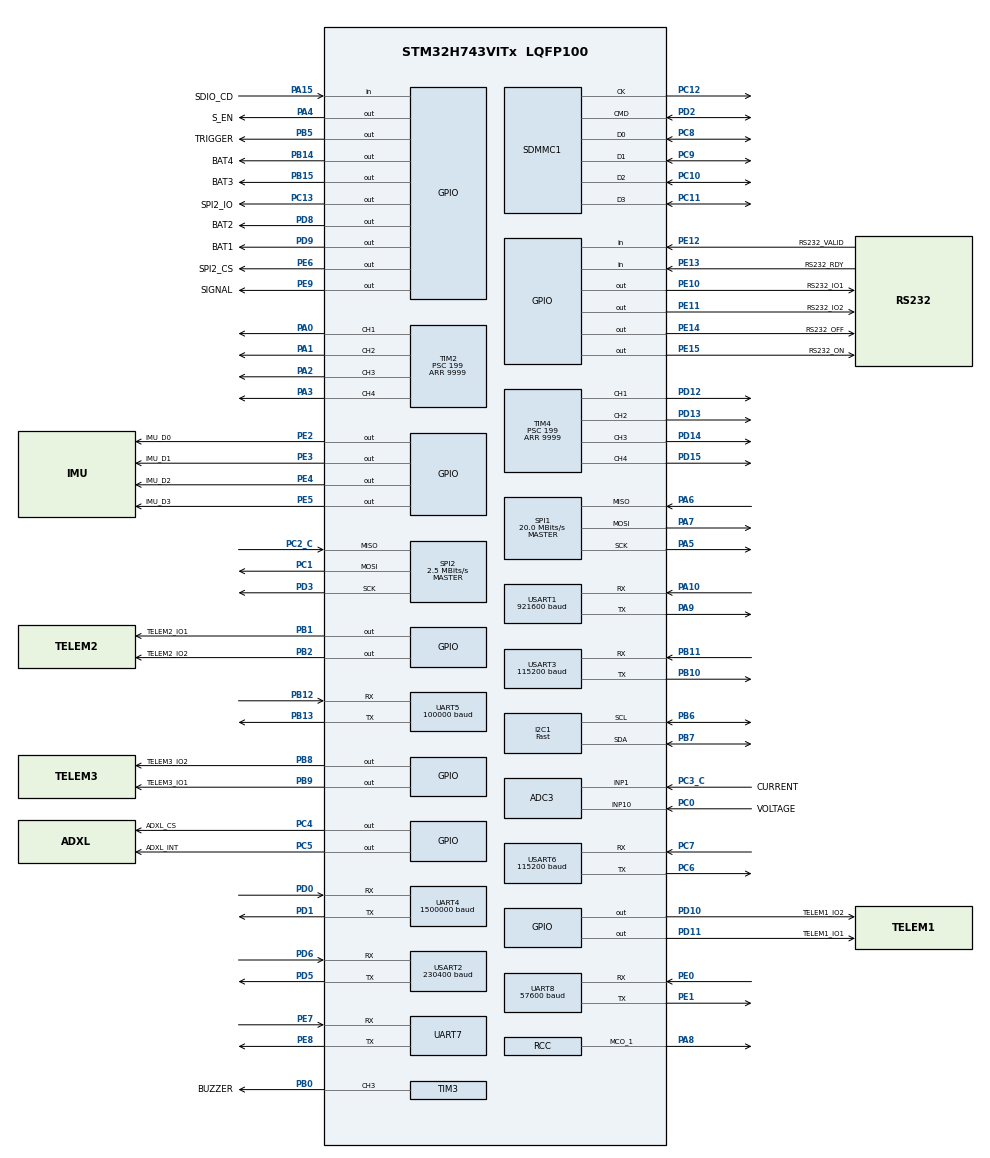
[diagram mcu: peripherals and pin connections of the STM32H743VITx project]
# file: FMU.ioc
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ADC3.Channel-7\#ChannelRegularConversion=ADC_CHANNEL_1
ADC3.Channel-8\#ChannelRegularConversion=ADC_CHANNEL_10
ADC3.ClockPrescalerADC3=ADC_CLOCK_ASYNC_DIV4
ADC3.DiscontinuousConvMode=ENABLE
ADC3.NbrOfConversion=2
ADC3.NbrOfConversionFlag=1
ADC3.OffsetNumber-7\#ChannelRegularConversion=ADC_OFFSET_NONE
ADC3.OffsetNumber-8\#ChannelRegularConversion=ADC_OFFSET_NONE
ADC3.OffsetSignedSaturation-7\#ChannelRegularConversion=DISABLE
ADC3.OffsetSignedSaturation-8\#ChannelRegularConversion=DISABLE
ADC3.Rank-7\#ChannelRegularConversion=1
ADC3.Rank-8\#ChannelRegularConversion=2
ADC3.SamplingTime-7\#ChannelRegularConversion=ADC_SAMPLETIME_387CYCLES_5
ADC3.SamplingTime-8\#ChannelRegularConversion=ADC_SAMPLETIME_387CYCLES_5
Dma.Request0=UART5_RX
Dma.Request1=USART3_RX
Dma.Request2=UART4_RX
Dma.Request3=USART2_RX
Dma.Request4=UART8_TX
Dma.Request5=USART6_RX
Dma.Request6=USART1_TX
Dma.Request7=UART8_RX
Dma.UART4_RX.2.Direction=DMA_PERIPH_TO_MEMORY
Dma.UART4_RX.2.EventEnable=DISABLE
Dma.UART4_RX.2.FIFOMode=DMA_FIFOMODE_DISABLE
Dma.UART4_RX.2.Instance=DMA1_Stream2
Dma.UART4_RX.2.MemDataAlignment=DMA_MDATAALIGN_BYTE
Dma.UART4_RX.2.MemInc=DMA_MINC_ENABLE
Dma.UART4_RX.2.Mode=DMA_NORMAL
Dma.UART4_RX.2.PeriphDataAlignment=DMA_PDATAALIGN_BYTE
Dma.UART4_RX.2.PeriphInc=DMA_PINC_DISABLE
Dma.UART4_RX.2.Polarity=HAL_DMAMUX_REQ_GEN_RISING
Dma.UART4_RX.2.Priority=DMA_PRIORITY_LOW
Dma.UART4_RX.2.RequestNumber=1
Dma.UART4_RX.2.SignalID=NONE
Dma.UART4_RX.2.SyncEnable=DISABLE
Dma.UART4_RX.2.SyncPolarity=HAL_DMAMUX_SYNC_NO_EVENT
Dma.UART4_RX.2.SyncRequestNumber=1
Dma.UART4_RX.2.SyncSignalID=NONE
Dma.UART5_RX.0.Direction=DMA_PERIPH_TO_MEMORY
Dma.UART5_RX.0.EventEnable=DISABLE
Dma.UART5_RX.0.FIFOMode=DMA_FIFOMODE_DISABLE
Dma.UART5_RX.0.Instance=DMA1_Stream0
Dma.UART5_RX.0.MemDataAlignment=DMA_MDATAALIGN_BYTE
Dma.UART5_RX.0.MemInc=DMA_MINC_ENABLE
Dma.UART5_RX.0.Mode=DMA_NORMAL
Dma.UART5_RX.0.PeriphDataAlignment=DMA_PDATAALIGN_BYTE
Dma.UART5_RX.0.PeriphInc=DMA_PINC_DISABLE
Dma.UART5_RX.0.Polarity=HAL_DMAMUX_REQ_GEN_RISING
Dma.UART5_RX.0.Priority=DMA_PRIORITY_VERY_HIGH
Dma.UART5_RX.0.RequestNumber=1
Dma.UART5_RX.0.SignalID=NONE
Dma.UART5_RX.0.SyncEnable=DISABLE
Dma.UART5_RX.0.SyncPolarity=HAL_DMAMUX_SYNC_NO_EVENT
Dma.UART5_RX.0.SyncRequestNumber=1
Dma.UART5_RX.0.SyncSignalID=NONE
Dma.UART8_RX.7.Direction=DMA_PERIPH_TO_MEMORY
Dma.UART8_RX.7.EventEnable=DISABLE
Dma.UART8_RX.7.FIFOMode=DMA_FIFOMODE_DISABLE
Dma.UART8_RX.7.Instance=DMA2_Stream0
Dma.UART8_RX.7.MemDataAlignment=DMA_MDATAALIGN_BYTE
Dma.UART8_RX.7.MemInc=DMA_MINC_ENABLE
Dma.UART8_RX.7.Mode=DMA_NORMAL
Dma.UART8_RX.7.PeriphDataAlignment=DMA_PDATAALIGN_BYTE
Dma.UART8_RX.7.PeriphInc=DMA_PINC_DISABLE
Dma.UART8_RX.7.Polarity=HAL_DMAMUX_REQ_GEN_RISING
Dma.UART8_RX.7.Priority=DMA_PRIORITY_HIGH
Dma.UART8_RX.7.RequestNumber=1
Dma.UART8_RX.7.SignalID=NONE
Dma.UART8_RX.7.SyncEnable=DISABLE
Dma.UART8_RX.7.SyncPolarity=HAL_DMAMUX_SYNC_NO_EVENT
Dma.UART8_RX.7.SyncRequestNumber=1
Dma.UART8_RX.7.SyncSignalID=NONE
Dma.UART8_TX.4.Direction=DMA_MEMORY_TO_PERIPH
Dma.UART8_TX.4.EventEnable=DISABLE
Dma.UART8_TX.4.FIFOMode=DMA_FIFOMODE_DISABLE
Dma.UART8_TX.4.Instance=DMA1_Stream4
Dma.UART8_TX.4.MemDataAlignment=DMA_MDATAALIGN_BYTE
Dma.UART8_TX.4.MemInc=DMA_MINC_ENABLE
Dma.UART8_TX.4.Mode=DMA_NORMAL
Dma.UART8_TX.4.PeriphDataAlignment=DMA_PDATAALIGN_BYTE
Dma.UART8_TX.4.PeriphInc=DMA_PINC_DISABLE
Dma.UART8_TX.4.Polarity=HAL_DMAMUX_REQ_GEN_RISING
Dma.UART8_TX.4.Priority=DMA_PRIORITY_LOW
Dma.UART8_TX.4.RequestNumber=1
Dma.UART8_TX.4.SignalID=NONE
Dma.UART8_TX.4.SyncEnable=DISABLE
Dma.UART8_TX.4.SyncPolarity=HAL_DMAMUX_SYNC_NO_EVENT
Dma.UART8_TX.4.SyncRequestNumber=1
Dma.UART8_TX.4.SyncSignalID=NONE
Dma.USART1_TX.6.Direction=DMA_MEMORY_TO_PERIPH
Dma.USART1_TX.6.EventEnable=DISABLE
Dma.USART1_TX.6.FIFOMode=DMA_FIFOMODE_DISABLE
Dma.USART1_TX.6.Instance=DMA1_Stream6
Dma.USART1_TX.6.MemDataAlignment=DMA_MDATAALIGN_BYTE
Dma.USART1_TX.6.MemInc=DMA_MINC_ENABLE
Dma.USART1_TX.6.Mode=DMA_NORMAL
Dma.USART1_TX.6.PeriphDataAlignment=DMA_PDATAALIGN_BYTE
Dma.USART1_TX.6.PeriphInc=DMA_PINC_DISABLE
Dma.USART1_TX.6.Polarity=HAL_DMAMUX_REQ_GEN_RISING
Dma.USART1_TX.6.Priority=DMA_PRIORITY_LOW
Dma.USART1_TX.6.RequestNumber=1
Dma.USART1_TX.6.SignalID=NONE
Dma.USART1_TX.6.SyncEnable=DISABLE
Dma.USART1_TX.6.SyncPolarity=HAL_DMAMUX_SYNC_NO_EVENT
Dma.USART1_TX.6.SyncRequestNumber=1
Dma.USART1_TX.6.SyncSignalID=NONE
Dma.USART2_RX.3.Direction=DMA_PERIPH_TO_MEMORY
Dma.USART2_RX.3.EventEnable=DISABLE
Dma.USART2_RX.3.FIFOMode=DMA_FIFOMODE_DISABLE
Dma.USART2_RX.3.Instance=DMA1_Stream3
Dma.USART2_RX.3.MemDataAlignment=DMA_MDATAALIGN_BYTE
Dma.USART2_RX.3.MemInc=DMA_MINC_ENABLE
Dma.USART2_RX.3.Mode=DMA_NORMAL
Dma.USART2_RX.3.PeriphDataAlignment=DMA_PDATAALIGN_BYTE
Dma.USART2_RX.3.PeriphInc=DMA_PINC_DISABLE
Dma.USART2_RX.3.Polarity=HAL_DMAMUX_REQ_GEN_RISING
Dma.USART2_RX.3.Priority=DMA_PRIORITY_VERY_HIGH
Dma.USART2_RX.3.RequestNumber=1
Dma.USART2_RX.3.SignalID=NONE
Dma.USART2_RX.3.SyncEnable=DISABLE
Dma.USART2_RX.3.SyncPolarity=HAL_DMAMUX_SYNC_NO_EVENT
Dma.USART2_RX.3.SyncRequestNumber=1
Dma.USART2_RX.3.SyncSignalID=NONE
Dma.USART3_RX.1.Direction=DMA_PERIPH_TO_MEMORY
Dma.USART3_RX.1.EventEnable=DISABLE
Dma.USART3_RX.1.FIFOMode=DMA_FIFOMODE_DISABLE
Dma.USART3_RX.1.Instance=DMA1_Stream1
Dma.USART3_RX.1.MemDataAlignment=DMA_MDATAALIGN_BYTE
Dma.USART3_RX.1.MemInc=DMA_MINC_ENABLE
Dma.USART3_RX.1.Mode=DMA_NORMAL
Dma.USART3_RX.1.PeriphDataAlignment=DMA_PDATAALIGN_BYTE
Dma.USART3_RX.1.PeriphInc=DMA_PINC_DISABLE
Dma.USART3_RX.1.Polarity=HAL_DMAMUX_REQ_GEN_RISING
Dma.USART3_RX.1.Priority=DMA_PRIORITY_MEDIUM
Dma.USART3_RX.1.RequestNumber=1
Dma.USART3_RX.1.SignalID=NONE
Dma.USART3_RX.1.SyncEnable=DISABLE
Dma.USART3_RX.1.SyncPolarity=HAL_DMAMUX_SYNC_NO_EVENT
Dma.USART3_RX.1.SyncRequestNumber=1
Dma.USART3_RX.1.SyncSignalID=NONE
Dma.USART6_RX.5.Direction=DMA_PERIPH_TO_MEMORY
Dma.USART6_RX.5.EventEnable=DISABLE
Dma.USART6_RX.5.FIFOMode=DMA_FIFOMODE_DISABLE
Dma.USART6_RX.5.Instance=DMA1_Stream5
Dma.USART6_RX.5.MemDataAlignment=DMA_MDATAALIGN_BYTE
Dma.USART6_RX.5.MemInc=DMA_MINC_ENABLE
Dma.USART6_RX.5.Mode=DMA_NORMAL
Dma.USART6_RX.5.PeriphDataAlignment=DMA_PDATAALIGN_BYTE
Dma.USART6_RX.5.PeriphInc=DMA_PINC_DISABLE
Dma.USART6_RX.5.Polarity=HAL_DMAMUX_REQ_GEN_RISING
Dma.USART6_RX.5.Priority=DMA_PRIORITY_MEDIUM
Dma.USART6_RX.5.RequestNumber=1
Dma.USART6_RX.5.SignalID=NONE
Dma.USART6_RX.5.SyncEnable=DISABLE
Dma.USART6_RX.5.SyncPolarity=HAL_DMAMUX_SYNC_NO_EVENT
Dma.USART6_RX.5.SyncRequestNumber=1
Dma.USART6_RX.5.SyncSignalID=NONE
FATFS.BSP.number=1
FATFS._CODE_PAGE=936
FATFS._STRF_ENCODE=0
FATFS._USE_LFN=3
FATFS0.BSP.STBoard=false
FATFS0.BSP.api=Unknown
FATFS0.BSP.instance=PA15 (JTDI)
FATFS0.BSP.ip=GPIO
FATFS0.BSP.mode=Input
FATFS0.BSP.name=Detect_SDIO
FATFS0.BSP.solution=PA15 (JTDI)
FREERTOS.Tasks01=defaultTask,0,256,StartDefaultTask,Default,NULL,Dynamic,NULL,NULL
FREERTOS.configENABLE_BACKWARD_COMPATIBILITY=0
FREERTOS.configENABLE_FPU=1
FREERTOS.configGENERATE_RUN_TIME_STATS=1
FREERTOS.configMAX_PRIORITIES=32
FREERTOS.configMAX_TASK_NAME_LEN=50
FREERTOS.configMINIMAL_STACK_SIZE=64
FREERTOS.configTICK_RATE_HZ=200
FREERTOS.configUSE_COUNTING_SEMAPHORES=1
FREERTOS.configUSE_STATS_FORMATTING_FUNCTIONS=1
FREERTOS.configUSE_TIMERS=0
FREERTOS.configUSE_TRACE_FACILITY=1
I2C1.I2C_Speed_Mode=I2C_Fast
I2C1.Timing=0x009034B6
Mcu.Family=STM32H7
Mcu.Name=STM32H743VITx
Mcu.Package=LQFP100
NVIC.DMA1_Stream0_IRQn=true\:5\:0\:false\:false\:true\:true\:false\:true\:true
NVIC.DMA1_Stream1_IRQn=true\:5\:0\:false\:false\:true\:true\:false\:true\:true
NVIC.DMA1_Stream2_IRQn=true\:5\:0\:false\:false\:true\:true\:false\:true\:true
NVIC.DMA1_Stream3_IRQn=true\:5\:0\:false\:false\:true\:true\:false\:true\:true
NVIC.DMA1_Stream4_IRQn=true\:5\:0\:false\:false\:true\:true\:false\:true\:true
NVIC.DMA1_Stream5_IRQn=true\:5\:0\:false\:false\:true\:true\:false\:true\:true
NVIC.DMA1_Stream6_IRQn=true\:5\:0\:false\:false\:true\:true\:false\:true\:true
NVIC.DMA2_Stream0_IRQn=true\:5\:0\:false\:false\:true\:true\:false\:true\:true
NVIC.PriorityGroup=NVIC_PRIORITYGROUP_4
NVIC.SDMMC1_IRQn=true\:6\:0\:true\:false\:true\:true\:true\:true\:true
NVIC.TIM17_IRQn=true\:15\:0\:false\:false\:true\:false\:false\:true\:true
NVIC.TIM6_DAC_IRQn=true\:5\:0\:false\:false\:true\:true\:true\:true\:true
NVIC.TIM7_IRQn=true\:5\:0\:false\:false\:true\:true\:true\:true\:true
NVIC.TimeBase=TIM17_IRQn
NVIC.TimeBaseIP=TIM17
NVIC.UART5_IRQn=true\:5\:0\:true\:false\:true\:true\:true\:true\:true
NVIC.UART8_IRQn=true\:5\:0\:false\:false\:true\:true\:true\:true\:true
NVIC.USART1_IRQn=true\:5\:0\:false\:false\:true\:true\:true\:true\:true
NVIC.USART2_IRQn=true\:6\:0\:true\:false\:true\:true\:true\:true\:true
NVIC.USART3_IRQn=true\:9\:0\:true\:false\:true\:true\:true\:true\:true
NVIC.USART6_IRQn=true\:5\:0\:false\:false\:true\:true\:true\:true\:true
PA0.Signal=S_TIM2_CH1_ETR
PA1.Signal=S_TIM2_CH2
PA10.Mode=Asynchronous
PA10.Signal=USART1_RX
PA13\ (JTMS/SWDIO).Mode=Serial_Wire
PA13\ (JTMS/SWDIO).Signal=DEBUG_JTMS-SWDIO
PA14\ (JTCK/SWCLK).Mode=Serial_Wire
PA14\ (JTCK/SWCLK).Signal=DEBUG_JTCK-SWCLK
PA15\ (JTDI).GPIO_Label=SDIO_CD
PA15\ (JTDI).Signal=GPIO_Input
PA2.Signal=S_TIM2_CH3
PA3.Signal=S_TIM2_CH4
PA4.GPIO_Label=S_EN
PA4.GPIO_ModeDefaultOutputPP=GPIO_MODE_OUTPUT_OD
PA4.GPIO_PuPd=GPIO_NOPULL
PA4.PinState=GPIO_PIN_SET
PA4.Signal=GPIO_Output
PA5.Mode=Full_Duplex_Master
PA5.Signal=SPI1_SCK
PA6.Mode=Full_Duplex_Master
PA6.Signal=SPI1_MISO
PA7.Mode=Full_Duplex_Master
PA7.Signal=SPI1_MOSI
PA8.Mode=Clock-out-1
PA8.Signal=RCC_MCO_1
PA9.Mode=Asynchronous
PA9.Signal=USART1_TX
PB0.GPIO_Label=BUZZER
PB0.Signal=S_TIM3_CH3
PB1.GPIO_Label=TELEM2_IO1
PB1.GPIO_PuPd=GPIO_PULLDOWN
PB1.GPIO_Speed=GPIO_SPEED_FREQ_LOW
PB1.PinState=GPIO_PIN_RESET
PB1.Signal=GPIO_Output
PB10.Mode=Asynchronous
PB10.Signal=USART3_TX
PB11.Mode=Asynchronous
PB11.Signal=USART3_RX
PB12.Mode=Asynchronous
PB12.Signal=UART5_RX
PB13.Mode=Asynchronous
PB13.Signal=UART5_TX
PB14.GPIO_Label=BAT4
PB14.GPIO_PuPd=GPIO_PULLDOWN
PB14.GPIO_Speed=GPIO_SPEED_FREQ_HIGH
PB14.PinState=GPIO_PIN_SET
PB14.Signal=GPIO_Output
PB15.GPIO_Label=BAT3
PB15.GPIO_PuPd=GPIO_PULLDOWN
PB15.GPIO_Speed=GPIO_SPEED_FREQ_HIGH
PB15.Signal=GPIO_Output
PB2.GPIO_Label=TELEM2_IO2
PB2.GPIO_PuPd=GPIO_PULLDOWN
PB2.GPIO_Speed=GPIO_SPEED_FREQ_LOW
PB2.Signal=GPIO_Output
PB5.GPIO_Label=TRIGGER
PB5.GPIO_PuPd=GPIO_PULLDOWN
PB5.GPIO_Speed=GPIO_SPEED_FREQ_VERY_HIGH
PB5.PinState=GPIO_PIN_SET
PB5.Signal=GPIO_Output
PB6.Mode=I2C
PB6.Signal=I2C1_SCL
PB7.Mode=I2C
PB7.Signal=I2C1_SDA
PB8.GPIO_Label=TELEM3_IO2
PB8.GPIO_PuPd=GPIO_PULLDOWN
PB8.Signal=GPIO_Output
PB9.GPIO_Label=TELEM3_IO1
PB9.GPIO_PuPd=GPIO_PULLDOWN
PB9.Signal=GPIO_Output
PC0.GPIO_Label=VOLTAGE
PC0.Signal=ADCx_INP10
PC1.Mode=Full_Duplex_Master
PC1.Signal=SPI2_MOSI
PC10.Mode=SD_4_bits_Wide_bus
PC10.Signal=SDMMC1_D2
PC11.Mode=SD_4_bits_Wide_bus
PC11.Signal=SDMMC1_D3
PC12.Mode=SD_4_bits_Wide_bus
PC12.Signal=SDMMC1_CK
PC13.GPIO_Label=SPI2_IO
PC13.GPIO_PuPd=GPIO_PULLDOWN
PC13.PinState=GPIO_PIN_RESET
PC13.Signal=GPIO_Output
PC2_C.Mode=Full_Duplex_Master
PC2_C.Signal=SPI2_MISO
PC3_C.GPIO_Label=CURRENT
PC3_C.Mode=IN1-Single-Ended
PC3_C.Signal=ADC3_INP1
PC4.GPIO_Label=ADXL_CS
PC4.GPIO_PuPd=GPIO_PULLUP
PC4.GPIO_Speed=GPIO_SPEED_FREQ_HIGH
PC4.PinState=GPIO_PIN_SET
PC4.Signal=GPIO_Output
PC5.GPIO_Label=ADXL_INT
PC5.GPIO_PuPd=GPIO_PULLUP
PC5.GPIO_Speed=GPIO_SPEED_FREQ_HIGH
PC5.PinState=GPIO_PIN_SET
PC5.Signal=GPIO_Output
PC6.Mode=Asynchronous
PC6.Signal=USART6_TX
PC7.Mode=Asynchronous
PC7.Signal=USART6_RX
PC8.Mode=SD_4_bits_Wide_bus
PC8.Signal=SDMMC1_D0
PC9.Mode=SD_4_bits_Wide_bus
PC9.Signal=SDMMC1_D1
PD0.Mode=Asynchronous
PD0.Signal=UART4_RX
PD1.Mode=Asynchronous
PD1.Signal=UART4_TX
PD10.GPIO_Label=TELEM1_IO2
PD10.GPIO_PuPd=GPIO_PULLDOWN
PD10.Signal=GPIO_Output
PD11.GPIO_Label=TELEM1_IO1
PD11.GPIO_PuPd=GPIO_PULLDOWN
PD11.Signal=GPIO_Output
PD12.Signal=S_TIM4_CH1
PD13.Signal=S_TIM4_CH2
PD14.Signal=S_TIM4_CH3
PD15.Signal=S_TIM4_CH4
PD2.Mode=SD_4_bits_Wide_bus
PD2.Signal=SDMMC1_CMD
PD3.Mode=Full_Duplex_Master
PD3.Signal=SPI2_SCK
PD5.Mode=Asynchronous
PD5.Signal=USART2_TX
PD6.Mode=Asynchronous
PD6.Signal=USART2_RX
PD8.GPIO_Label=BAT2
PD8.GPIO_PuPd=GPIO_PULLDOWN
PD8.GPIO_Speed=GPIO_SPEED_FREQ_HIGH
PD8.Signal=GPIO_Output
PD9.GPIO_Label=BAT1
PD9.GPIO_PuPd=GPIO_PULLDOWN
PD9.GPIO_Speed=GPIO_SPEED_FREQ_HIGH
PD9.PinState=GPIO_PIN_RESET
PD9.Signal=GPIO_Output
PE0.Mode=Asynchronous
PE0.Signal=UART8_RX
PE1.Mode=Asynchronous
PE1.Signal=UART8_TX
PE10.GPIO_Label=RS232_IO1
PE10.GPIO_PuPd=GPIO_PULLDOWN
PE10.GPIO_Speed=GPIO_SPEED_FREQ_LOW
PE10.Signal=GPIO_Output
PE11.GPIO_Label=RS232_IO2
PE11.GPIO_PuPd=GPIO_PULLDOWN
PE11.Signal=GPIO_Output
PE12.GPIO_Label=RS232_VALID
PE12.Signal=GPIO_Input
PE13.GPIO_Label=RS232_RDY
PE13.Signal=GPIO_Input
PE14.GPIO_Label=RS232_OFF
PE14.PinState=GPIO_PIN_SET
PE14.Signal=GPIO_Output
PE15.GPIO_Label=RS232_ON
PE15.PinState=GPIO_PIN_SET
PE15.Signal=GPIO_Output
PE2.GPIO_Label=IMU_D0
PE2.GPIO_PuPd=GPIO_PULLDOWN
PE2.Signal=GPIO_Output
PE3.GPIO_Label=IMU_D1
PE3.GPIO_PuPd=GPIO_PULLDOWN
PE3.Signal=GPIO_Output
PE4.GPIO_Label=IMU_D2
PE4.GPIO_PuPd=GPIO_PULLDOWN
PE4.Signal=GPIO_Output
PE5.GPIO_Label=IMU_D3
PE5.GPIO_PuPd=GPIO_PULLDOWN
PE5.GPIO_Speed=GPIO_SPEED_FREQ_LOW
PE5.Signal=GPIO_Output
PE6.GPIO_Label=SPI2_CS
PE6.GPIO_PuPd=GPIO_PULLUP
PE6.GPIO_Speed=GPIO_SPEED_FREQ_HIGH
PE6.PinState=GPIO_PIN_SET
PE6.Signal=GPIO_Output
PE7.Mode=Asynchronous
PE7.Signal=UART7_RX
PE8.Mode=Asynchronous
PE8.Signal=UART7_TX
PE9.GPIO_Label=SIGNAL
PE9.GPIO_ModeDefaultOutputPP=GPIO_MODE_OUTPUT_PP
PE9.GPIO_PuPd=GPIO_PULLDOWN
PE9.PinState=GPIO_PIN_SET
PE9.Signal=GPIO_Output
PH0-OSC_IN\ (PH0).Mode=HSE-External-Oscillator
PH0-OSC_IN\ (PH0).Signal=RCC_OSC_IN
PH1-OSC_OUT\ (PH1).Mode=HSE-External-Oscillator
PH1-OSC_OUT\ (PH1).Signal=RCC_OSC_OUT
ProjectManager.HeapSize=0x1000
ProjectManager.StackSize=0x2000
ProjectManager.TargetToolchain=MDK-ARM V5
RCC.ADCFreq_Value=72000000
RCC.APB1Freq_Value=100000000
RCC.APB2Freq_Value=100000000
RCC.APB3Freq_Value=100000000
RCC.APB4Freq_Value=100000000
RCC.CortexFreq_Value=400000000
RCC.D1PPRE=RCC_APB3_DIV2
RCC.D2PPRE1=RCC_APB1_DIV2
RCC.D2PPRE2=RCC_APB2_DIV2
RCC.D3PPRE=RCC_APB4_DIV2
RCC.DIVM1=1
RCC.DIVM2=1
RCC.DIVM3=1
RCC.DIVN1=100
RCC.DIVN2=36
RCC.DIVN3=24
RCC.DIVP2=4
RCC.DIVQ1=20
RCC.DIVQ2=4
RCC.DIVQ3=4
RCC.DIVR2=1
RCC.EnbaleCSS=false
RCC.HCLKFreq_Value=200000000
RCC.HPRE=RCC_HCLK_DIV2
RCC.HSE_VALUE=8000000
RCC.PLL1_VCI_Range-AdvancedSettings=RCC_PLL1VCIRANGE_0
RCC.PLL1_VCO_SEL-AdvancedSettings=RCC_PLL1VCOWIDE
RCC.PLL2FRACN=0
RCC.PLL2_VCI_Range-AdvancedSettings=RCC_PLL2VCIRANGE_0
RCC.PLL2_VCO_SEL-AdvancedSettings=RCC_PLL2VCOMEDIUM
RCC.PLL3FRACN=0
RCC.PLLFRACN=0
RCC.PLLSourceVirtual=RCC_PLLSOURCE_HSE
RCC.RCC_MCO1Source=RCC_MCO1SOURCE_PLL1QCLK
RCC.SYSCLKFreq_VALUE=400000000
RCC.SYSCLKSource=RCC_SYSCLKSOURCE_PLLCLK
RCC.USBCLockSelection=RCC_USBCLKSOURCE_PLL3
RCC.USBFreq_Value=48000000
SDMMC1.ClockDiv=2
SH.ADCx_INP10.0=ADC3_INP10,IN10-Single-Ended
SH.S_TIM2_CH1_ETR.0=TIM2_CH1,PWM Generation1 CH1
SH.S_TIM2_CH2.0=TIM2_CH2,PWM Generation2 CH2
SH.S_TIM2_CH3.0=TIM2_CH3,PWM Generation3 CH3
SH.S_TIM2_CH4.0=TIM2_CH4,PWM Generation4 CH4
SH.S_TIM3_CH3.0=TIM3_CH3,PWM Generation3 CH3
SH.S_TIM4_CH1.0=TIM4_CH1,PWM Generation1 CH1
SH.S_TIM4_CH2.0=TIM4_CH2,PWM Generation2 CH2
SH.S_TIM4_CH3.0=TIM4_CH3,PWM Generation3 CH3
SH.S_TIM4_CH4.0=TIM4_CH4,PWM Generation4 CH4
SPI1.CalculateBaudRate=20.0 MBits/s
SPI1.DataSize=SPI_DATASIZE_8BIT
SPI1.Direction=SPI_DIRECTION_2LINES
SPI1.Mode=SPI_MODE_MASTER
SPI1.VirtualType=VM_MASTER
SPI2.BaudRatePrescaler=SPI_BAUDRATEPRESCALER_16
SPI2.CalculateBaudRate=2.5 MBits/s
SPI2.Direction=SPI_DIRECTION_2LINES
SPI2.Mode=SPI_MODE_MASTER
SPI2.VirtualType=VM_MASTER
TIM2.AutoReloadPreload=TIM_AUTORELOAD_PRELOAD_DISABLE
TIM2.Channel-PWM\ Generation1\ CH1=TIM_CHANNEL_1
TIM2.Channel-PWM\ Generation2\ CH2=TIM_CHANNEL_2
TIM2.Channel-PWM\ Generation3\ CH3=TIM_CHANNEL_3
TIM2.Channel-PWM\ Generation4\ CH4=TIM_CHANNEL_4
TIM2.Period=9999
TIM2.Prescaler=199
TIM2.Pulse-PWM\ Generation1\ CH1=500
TIM2.Pulse-PWM\ Generation2\ CH2=1000
TIM2.Pulse-PWM\ Generation3\ CH3=1500
TIM2.Pulse-PWM\ Generation4\ CH4=2000
TIM3.Channel-PWM\ Generation3\ CH3=TIM_CHANNEL_3
TIM3.Period=249
TIM3.Prescaler=99
TIM3.Pulse-PWM\ Generation3\ CH3=10
TIM4.Channel-PWM\ Generation1\ CH1=TIM_CHANNEL_1
TIM4.Channel-PWM\ Generation2\ CH2=TIM_CHANNEL_2
TIM4.Channel-PWM\ Generation3\ CH3=TIM_CHANNEL_3
TIM4.Channel-PWM\ Generation4\ CH4=TIM_CHANNEL_4
TIM4.Period=9999
TIM4.Prescaler=199
TIM4.Pulse-PWM\ Generation1\ CH1=1000
TIM4.Pulse-PWM\ Generation2\ CH2=1500
TIM4.Pulse-PWM\ Generation3\ CH3=2000
TIM4.Pulse-PWM\ Generation4\ CH4=2500
TIM5.Period=0xFFFFFFFF
TIM5.Prescaler=199
TIM6.Period=9999
TIM6.Prescaler=199
TIM7.Period=999
TIM7.Prescaler=9
UART4.BaudRate=1500000
UART5.BaudRate=100000
UART5.Parity=PARITY_EVEN
UART5.StopBits=UART_STOPBITS_2
UART5.WordLength=WORDLENGTH_9B
UART8.BaudRate=57600
USART1.BaudRate=921600
USART1.VirtualMode-Asynchronous=VM_ASYNC
USART2.BaudRate=230400
USART2.VirtualMode-Asynchronous=VM_ASYNC
USART3.BaudRate=115200
USART3.VirtualMode-Asynchronous=VM_ASYNC
USART6.BaudRate=115200
USART6.Mode=MODE_TX_RX
USART6.VirtualMode=VM_ASYNC
VP_FATFS_VS_SDIO.Mode=SDIO
VP_FREERTOS_VS_CMSIS_V1.Mode=CMSIS_V1
VP_SYS_VS_tim17.Mode=TIM17
VP_TIM2_VS_ClockSourceINT.Mode=Internal
VP_TIM3_VS_ClockSourceINT.Mode=Internal
VP_TIM4_VS_ClockSourceINT.Mode=Internal
VP_TIM5_VS_ClockSourceINT.Mode=Internal
VP_TIM6_VS_ClockSourceINT.Mode=Enable_Timer
VP_TIM7_VS_ClockSourceINT.Mode=Enable_Timer
board=custom

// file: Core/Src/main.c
/* USER CODE BEGIN Header */
/**
  ******************************************************************************
  * @file           : main.c
  * @brief          : Main program body
  ******************************************************************************
  * @attention
  *
  * Copyright (c) 2023 STMicroelectronics.
  * All rights reserved.
  *
  * This software is licensed under terms that can be found in the LICENSE file
  * in the root directory of this software component.
  * If no LICENSE file comes with this software, it is provided AS-IS.
  *
  ******************************************************************************
  */
/* USER CODE END Header */
#include "main.h"
#include "cmsis_os.h"
#include "fatfs.h"

/* USER CODE BEGIN Includes */
#include "string.h"
#include "stdio.h"
#include "delay.h"
#include "taskinit.h"
#include "imu.h"
#include "control.h"
#include "ms5525.h"
/* USER CODE END Includes */

ADC_HandleTypeDef hadc3;

I2C_HandleTypeDef hi2c1;

SD_HandleTypeDef hsd1;

SPI_HandleTypeDef hspi1;
SPI_HandleTypeDef hspi2;

TIM_HandleTypeDef htim2;
TIM_HandleTypeDef htim3;
TIM_HandleTypeDef htim4;
TIM_HandleTypeDef htim5;
TIM_HandleTypeDef htim6;
TIM_HandleTypeDef htim7;

UART_HandleTypeDef huart4;
UART_HandleTypeDef huart5;
UART_HandleTypeDef huart7;
UART_HandleTypeDef huart8;
UART_HandleTypeDef huart1;
UART_HandleTypeDef huart2;
UART_HandleTypeDef huart3;
UART_HandleTypeDef huart6;
DMA_HandleTypeDef hdma_uart4_rx;
DMA_HandleTypeDef hdma_uart5_rx;
DMA_HandleTypeDef hdma_uart8_tx;
DMA_HandleTypeDef hdma_uart8_rx;
DMA_HandleTypeDef hdma_usart1_tx;
DMA_HandleTypeDef hdma_usart2_rx;
DMA_HandleTypeDef hdma_usart3_rx;
DMA_HandleTypeDef hdma_usart6_rx;

osThreadId defaultTaskHandle;
/* USER CODE BEGIN PV */
unsigned long FreeRTOSRunTimeTicks = 0;
BYTE work[_MAX_SS];

/* USER CODE END PV */

void SystemClock_Config(void);
static void MX_GPIO_Init(void);
static void MX_DMA_Init(void);
static void MX_SDMMC1_SD_Init(void);
static void MX_SPI1_Init(void);
static void MX_SPI2_Init(void);
static void MX_UART4_Init(void);
static void MX_UART5_Init(void);
static void MX_USART1_UART_Init(void);
static void MX_USART2_UART_Init(void);
static void MX_USART3_UART_Init(void);
static void MX_ADC3_Init(void);
static void MX_TIM2_Init(void);
static void MX_TIM3_Init(void);
static void MX_TIM4_Init(void);
static void MX_UART7_Init(void);
static void MX_UART8_Init(void);
static void MX_USART6_UART_Init(void);
static void MX_I2C1_Init(void);
static void MX_TIM5_Init(void);
static void MX_TIM7_Init(void);
static void MX_TIM6_Init(void);
void StartDefaultTask(void const * argument);

int main(void)
{

  /* MCU Configuration--------------------------------------------------------*/

  /* Reset of all peripherals, Initializes the Flash interface and the Systick. */
  HAL_Init();

  /* Configure the system clock */
  SystemClock_Config();

  /* Initialize all configured peripherals */
  MX_GPIO_Init();
  MX_DMA_Init();
  MX_SDMMC1_SD_Init();
  MX_SPI1_Init();
  MX_SPI2_Init();
  MX_UART4_Init();
  MX_UART5_Init();
  MX_USART1_UART_Init();
  MX_USART2_UART_Init();
  MX_USART3_UART_Init();
  MX_ADC3_Init();
  MX_TIM2_Init();
  MX_TIM3_Init();
  MX_TIM4_Init();
  MX_UART7_Init();
  MX_UART8_Init();
  MX_USART6_UART_Init();
  MX_I2C1_Init();
  MX_FATFS_Init();
  MX_TIM5_Init();
  MX_TIM7_Init();
  MX_TIM6_Init();
  /* USER CODE BEGIN 2 */
	HAL_TIM_Base_Start(&htim2);
	HAL_TIM_PWM_Start(&htim2,TIM_CHANNEL_1);
	HAL_TIM_PWM_Start(&htim2,TIM_CHANNEL_2);
	HAL_TIM_PWM_Start(&htim2,TIM_CHANNEL_3);
	HAL_TIM_PWM_Start(&htim2,TIM_CHANNEL_4);
	HAL_TIM_Base_Start(&htim4);
	HAL_TIM_PWM_Start(&htim4,TIM_CHANNEL_1);
	HAL_TIM_PWM_Start(&htim4,TIM_CHANNEL_2);
	HAL_TIM_PWM_Start(&htim4,TIM_CHANNEL_3);
	HAL_TIM_PWM_Start(&htim4,TIM_CHANNEL_4);
//	HAL_TIM_PWM_Start(&htim3,TIM_CHANNEL_3);
//	HAL_TIM_PWM_Stop(&htim3,TIM_CHANNEL_3);
	ServoSet(ServoChannel_1,0);
	ServoSet(ServoChannel_2,0);
	__HAL_TIM_SET_COMPARE(&htim2,TIM_CHANNEL_3,1000);
	ServoSet(ServoChannel_4,0);
	ServoSet(ServoChannel_5,0);
	ServoSet(ServoChannel_6,0);
	ServoSet(ServoChannel_7,0);
	ServoSet(ServoChannel_8,0);
	TaskCreate();//创建任务并启动调度器

  /* USER CODE END 2 */

  /* Create the thread(s) */
  /* definition and creation of defaultTask */
  osThreadDef(defaultTask, StartDefaultTask, osPriorityNormal, 0, 256);
  defaultTaskHandle = osThreadCreate(osThread(defaultTask), NULL);

  /* Start scheduler */
  osKernelStart();

  /* We should never get here as control is now taken by the scheduler */

  /* Infinite loop */
  while (1)
  {

    /* USER CODE BEGIN 3 */
		ServoSet(ServoChannel_1,0);
		ServoSet(ServoChannel_2,0);
		ServoSet(ServoChannel_3,0);
		ServoSet(ServoChannel_4,0);
		ServoSet(ServoChannel_5,0);
		ServoSet(ServoChannel_6,0);
		ServoSet(ServoChannel_7,0);
		ServoSet(ServoChannel_8,0);
		HAL_Delay(3000000);
//		ServoSet(ServoChannel_1,20);
//		ServoSet(ServoChannel_2,20);
//		ServoSet(ServoChannel_3,20);
//		ServoSet(ServoChannel_4,20);
//		ServoSet(ServoChannel_5,20);
//		ServoSet(ServoChannel_6,20);
//		ServoSet(ServoChannel_7,20);
//		ServoSet(ServoChannel_8,20);
		HAL_Delay(1000000);
//		MS5525_Reset(0x76);
//		MS5525_Reset(0x77);
//		MS5525_Calibration(0x76,&MS5525_StaticData);
//		MS5525_Calibration(0x77,&MS5525_TotalData);
//		while(1)
//		{
//			MS5525_Ret = MS5525_Measure();
//			MS5525_Converse(&MS5525_StaticData);
//			MS5525_Converse(&MS5525_TotalData);
//			HAL_GPIO_TogglePin(SIGNAL_GPIO_Port,SIGNAL_Pin);
//			if(MS5525_Ret == MS5525_OK) printf("pre:%f  tem:%f  pre:%f  tem:%f\r\n",MS5525_StaticData.pre,MS5525_StaticData.temp,MS5525_TotalData.pre,MS5525_TotalData.temp);
//			HAL_Delay(100000);
//		}
//路径测试程序
	}
  /* USER CODE END 3 */
}

void SystemClock_Config(void)
{
  RCC_OscInitTypeDef RCC_OscInitStruct = {0};
  RCC_ClkInitTypeDef RCC_ClkInitStruct = {0};

  /** Supply configuration update enable
  */
  HAL_PWREx_ConfigSupply(PWR_LDO_SUPPLY);

  /** Configure the main internal regulator output voltage
  */
  __HAL_PWR_VOLTAGESCALING_CONFIG(PWR_REGULATOR_VOLTAGE_SCALE1);

  while(!__HAL_PWR_GET_FLAG(PWR_FLAG_VOSRDY)) {}

  /** Initializes the RCC Oscillators according to the specified parameters
  * in the RCC_OscInitTypeDef structure.
  */
  RCC_OscInitStruct.OscillatorType = RCC_OSCILLATORTYPE_HSE;
  RCC_OscInitStruct.HSEState = RCC_HSE_ON;
  RCC_OscInitStruct.PLL.PLLState = RCC_PLL_ON;
  RCC_OscInitStruct.PLL.PLLSource = RCC_PLLSOURCE_HSE;
  RCC_OscInitStruct.PLL.PLLM = 1;
  RCC_OscInitStruct.PLL.PLLN = 100;
  RCC_OscInitStruct.PLL.PLLP = 2;
  RCC_OscInitStruct.PLL.PLLQ = 20;
  RCC_OscInitStruct.PLL.PLLR = 2;
  RCC_OscInitStruct.PLL.PLLRGE = RCC_PLL1VCIRANGE_3;
  RCC_OscInitStruct.PLL.PLLVCOSEL = RCC_PLL1VCOWIDE;
  RCC_OscInitStruct.PLL.PLLFRACN = 0;
  if (HAL_RCC_OscConfig(&RCC_OscInitStruct) != HAL_OK)
  {
    Error_Handler();
  }

  /** Initializes the CPU, AHB and APB buses clocks
  */
  RCC_ClkInitStruct.ClockType = RCC_CLOCKTYPE_HCLK|RCC_CLOCKTYPE_SYSCLK
                              |RCC_CLOCKTYPE_PCLK1|RCC_CLOCKTYPE_PCLK2
                              |RCC_CLOCKTYPE_D3PCLK1|RCC_CLOCKTYPE_D1PCLK1;
  RCC_ClkInitStruct.SYSCLKSource = RCC_SYSCLKSOURCE_PLLCLK;
  RCC_ClkInitStruct.SYSCLKDivider = RCC_SYSCLK_DIV1;
  RCC_ClkInitStruct.AHBCLKDivider = RCC_HCLK_DIV2;
  RCC_ClkInitStruct.APB3CLKDivider = RCC_APB3_DIV2;
  RCC_ClkInitStruct.APB1CLKDivider = RCC_APB1_DIV2;
  RCC_ClkInitStruct.APB2CLKDivider = RCC_APB2_DIV2;
  RCC_ClkInitStruct.APB4CLKDivider = RCC_APB4_DIV2;

  if (HAL_RCC_ClockConfig(&RCC_ClkInitStruct, FLASH_LATENCY_2) != HAL_OK)
  {
    Error_Handler();
  }
  __HAL_RCC_PLLCLKOUT_ENABLE(RCC_PLL1_DIVQ);
  HAL_RCC_MCOConfig(RCC_MCO1, RCC_MCO1SOURCE_PLL1QCLK, RCC_MCODIV_1);
}

static void MX_ADC3_Init(void)
{

  ADC_ChannelConfTypeDef sConfig = {0};

  /** Common config
  */
  hadc3.Instance = ADC3;
  hadc3.Init.ClockPrescaler = ADC_CLOCK_ASYNC_DIV4;
  hadc3.Init.ScanConvMode = ADC_SCAN_ENABLE;
  hadc3.Init.EOCSelection = ADC_EOC_SINGLE_CONV;
  hadc3.Init.LowPowerAutoWait = DISABLE;
  hadc3.Init.ContinuousConvMode = DISABLE;
  hadc3.Init.NbrOfConversion = 2;
  hadc3.Init.DiscontinuousConvMode = ENABLE;
  hadc3.Init.NbrOfDiscConversion = 1;
  hadc3.Init.ExternalTrigConv = ADC_SOFTWARE_START;
  hadc3.Init.ExternalTrigConvEdge = ADC_EXTERNALTRIGCONVEDGE_NONE;
  hadc3.Init.ConversionDataManagement = ADC_CONVERSIONDATA_DR;
  hadc3.Init.Overrun = ADC_OVR_DATA_PRESERVED;
  hadc3.Init.LeftBitShift = ADC_LEFTBITSHIFT_NONE;
  hadc3.Init.OversamplingMode = DISABLE;
  hadc3.Init.Oversampling.Ratio = 1;
  if (HAL_ADC_Init(&hadc3) != HAL_OK)
  {
    Error_Handler();
  }
  hadc3.Init.Resolution = ADC_RESOLUTION_16B;
  if (HAL_ADC_Init(&hadc3) != HAL_OK)
  {
    Error_Handler();
  }

  /** Configure Regular Channel
  */
  sConfig.Channel = ADC_CHANNEL_1;
  sConfig.Rank = ADC_REGULAR_RANK_1;
  sConfig.SamplingTime = ADC_SAMPLETIME_387CYCLES_5;
  sConfig.SingleDiff = ADC_SINGLE_ENDED;
  sConfig.OffsetNumber = ADC_OFFSET_NONE;
  sConfig.Offset = 0;
  sConfig.OffsetSignedSaturation = DISABLE;
  if (HAL_ADC_ConfigChannel(&hadc3, &sConfig) != HAL_OK)
  {
    Error_Handler();
  }

  /** Configure Regular Channel
  */
  sConfig.Channel = ADC_CHANNEL_10;
  sConfig.Rank = ADC_REGULAR_RANK_2;
  if (HAL_ADC_ConfigChannel(&hadc3, &sConfig) != HAL_OK)
  {
    Error_Handler();
  }

}

static void MX_I2C1_Init(void)
{

  hi2c1.Instance = I2C1;
  hi2c1.Init.Timing = 0x009034B6;
  hi2c1.Init.OwnAddress1 = 0;
  hi2c1.Init.AddressingMode = I2C_ADDRESSINGMODE_7BIT;
  hi2c1.Init.DualAddressMode = I2C_DUALADDRESS_DISABLE;
  hi2c1.Init.OwnAddress2 = 0;
  hi2c1.Init.OwnAddress2Masks = I2C_OA2_NOMASK;
  hi2c1.Init.GeneralCallMode = I2C_GENERALCALL_DISABLE;
  hi2c1.Init.NoStretchMode = I2C_NOSTRETCH_DISABLE;
  if (HAL_I2C_Init(&hi2c1) != HAL_OK)
  {
    Error_Handler();
  }

  /** Configure Analogue filter
  */
  if (HAL_I2CEx_ConfigAnalogFilter(&hi2c1, I2C_ANALOGFILTER_ENABLE) != HAL_OK)
  {
    Error_Handler();
  }

  /** Configure Digital filter
  */
  if (HAL_I2CEx_ConfigDigitalFilter(&hi2c1, 0) != HAL_OK)
  {
    Error_Handler();
  }

}

static void MX_SDMMC1_SD_Init(void)
{

  hsd1.Instance = SDMMC1;
  hsd1.Init.ClockEdge = SDMMC_CLOCK_EDGE_RISING;
  hsd1.Init.ClockPowerSave = SDMMC_CLOCK_POWER_SAVE_DISABLE;
  hsd1.Init.BusWide = SDMMC_BUS_WIDE_4B;
  hsd1.Init.HardwareFlowControl = SDMMC_HARDWARE_FLOW_CONTROL_DISABLE;
  hsd1.Init.ClockDiv = 2;

}

static void MX_SPI1_Init(void)
{

  /* SPI1 parameter configuration*/
  hspi1.Instance = SPI1;
  hspi1.Init.Mode = SPI_MODE_MASTER;
  hspi1.Init.Direction = SPI_DIRECTION_2LINES;
  hspi1.Init.DataSize = SPI_DATASIZE_8BIT;
  hspi1.Init.CLKPolarity = SPI_POLARITY_LOW;
  hspi1.Init.CLKPhase = SPI_PHASE_1EDGE;
  hspi1.Init.NSS = SPI_NSS_SOFT;
  hspi1.Init.BaudRatePrescaler = SPI_BAUDRATEPRESCALER_2;
  hspi1.Init.FirstBit = SPI_FIRSTBIT_MSB;
  hspi1.Init.TIMode = SPI_TIMODE_DISABLE;
  hspi1.Init.CRCCalculation = SPI_CRCCALCULATION_DISABLE;
  hspi1.Init.CRCPolynomial = 0x0;
  hspi1.Init.NSSPMode = SPI_NSS_PULSE_ENABLE;
  hspi1.Init.NSSPolarity = SPI_NSS_POLARITY_LOW;
  hspi1.Init.FifoThreshold = SPI_FIFO_THRESHOLD_01DATA;
  hspi1.Init.TxCRCInitializationPattern = SPI_CRC_INITIALIZATION_ALL_ZERO_PATTERN;
  hspi1.Init.RxCRCInitializationPattern = SPI_CRC_INITIALIZATION_ALL_ZERO_PATTERN;
  hspi1.Init.MasterSSIdleness = SPI_MASTER_SS_IDLENESS_00CYCLE;
  hspi1.Init.MasterInterDataIdleness = SPI_MASTER_INTERDATA_IDLENESS_00CYCLE;
  hspi1.Init.MasterReceiverAutoSusp = SPI_MASTER_RX_AUTOSUSP_DISABLE;
  hspi1.Init.MasterKeepIOState = SPI_MASTER_KEEP_IO_STATE_DISABLE;
  hspi1.Init.IOSwap = SPI_IO_SWAP_DISABLE;
  if (HAL_SPI_Init(&hspi1) != HAL_OK)
  {
    Error_Handler();
  }

}

static void MX_SPI2_Init(void)
{

  /* SPI2 parameter configuration*/
  hspi2.Instance = SPI2;
  hspi2.Init.Mode = SPI_MODE_MASTER;
  hspi2.Init.Direction = SPI_DIRECTION_2LINES;
  hspi2.Init.DataSize = SPI_DATASIZE_4BIT;
  hspi2.Init.CLKPolarity = SPI_POLARITY_LOW;
  hspi2.Init.CLKPhase = SPI_PHASE_1EDGE;
  hspi2.Init.NSS = SPI_NSS_SOFT;
  hspi2.Init.BaudRatePrescaler = SPI_BAUDRATEPRESCALER_16;
  hspi2.Init.FirstBit = SPI_FIRSTBIT_MSB;
  hspi2.Init.TIMode = SPI_TIMODE_DISABLE;
  hspi2.Init.CRCCalculation = SPI_CRCCALCULATION_DISABLE;
  hspi2.Init.CRCPolynomial = 0x0;
  hspi2.Init.NSSPMode = SPI_NSS_PULSE_ENABLE;
  hspi2.Init.NSSPolarity = SPI_NSS_POLARITY_LOW;
  hspi2.Init.FifoThreshold = SPI_FIFO_THRESHOLD_01DATA;
  hspi2.Init.TxCRCInitializationPattern = SPI_CRC_INITIALIZATION_ALL_ZERO_PATTERN;
  hspi2.Init.RxCRCInitializationPattern = SPI_CRC_INITIALIZATION_ALL_ZERO_PATTERN;
  hspi2.Init.MasterSSIdleness = SPI_MASTER_SS_IDLENESS_00CYCLE;
  hspi2.Init.MasterInterDataIdleness = SPI_MASTER_INTERDATA_IDLENESS_00CYCLE;
  hspi2.Init.MasterReceiverAutoSusp = SPI_MASTER_RX_AUTOSUSP_DISABLE;
  hspi2.Init.MasterKeepIOState = SPI_MASTER_KEEP_IO_STATE_DISABLE;
  hspi2.Init.IOSwap = SPI_IO_SWAP_DISABLE;
  if (HAL_SPI_Init(&hspi2) != HAL_OK)
  {
    Error_Handler();
  }

}

static void MX_TIM2_Init(void)
{

  TIM_ClockConfigTypeDef sClockSourceConfig = {0};
  TIM_MasterConfigTypeDef sMasterConfig = {0};
  TIM_OC_InitTypeDef sConfigOC = {0};

  htim2.Instance = TIM2;
  htim2.Init.Prescaler = 199;
  htim2.Init.CounterMode = TIM_COUNTERMODE_UP;
  htim2.Init.Period = 9999;
  htim2.Init.ClockDivision = TIM_CLOCKDIVISION_DIV1;
  htim2.Init.AutoReloadPreload = TIM_AUTORELOAD_PRELOAD_DISABLE;
  if (HAL_TIM_Base_Init(&htim2) != HAL_OK)
  {
    Error_Handler();
  }
  sClockSourceConfig.ClockSource = TIM_CLOCKSOURCE_INTERNAL;
  if (HAL_TIM_ConfigClockSource(&htim2, &sClockSourceConfig) != HAL_OK)
  {
    Error_Handler();
  }
  if (HAL_TIM_PWM_Init(&htim2) != HAL_OK)
  {
    Error_Handler();
  }
  sMasterConfig.MasterOutputTrigger = TIM_TRGO_RESET;
  sMasterConfig.MasterSlaveMode = TIM_MASTERSLAVEMODE_DISABLE;
  if (HAL_TIMEx_MasterConfigSynchronization(&htim2, &sMasterConfig) != HAL_OK)
  {
    Error_Handler();
  }
  sConfigOC.OCMode = TIM_OCMODE_PWM1;
  sConfigOC.Pulse = 500;
  sConfigOC.OCPolarity = TIM_OCPOLARITY_HIGH;
  sConfigOC.OCFastMode = TIM_OCFAST_DISABLE;
  if (HAL_TIM_PWM_ConfigChannel(&htim2, &sConfigOC, TIM_CHANNEL_1) != HAL_OK)
  {
    Error_Handler();
  }
  sConfigOC.Pulse = 1000;
  if (HAL_TIM_PWM_ConfigChannel(&htim2, &sConfigOC, TIM_CHANNEL_2) != HAL_OK)
  {
    Error_Handler();
  }
  sConfigOC.Pulse = 1500;
  if (HAL_TIM_PWM_ConfigChannel(&htim2, &sConfigOC, TIM_CHANNEL_3) != HAL_OK)
  {
    Error_Handler();
  }
  sConfigOC.Pulse = 2000;
  if (HAL_TIM_PWM_ConfigChannel(&htim2, &sConfigOC, TIM_CHANNEL_4) != HAL_OK)
  {
    Error_Handler();
  }
  HAL_TIM_MspPostInit(&htim2);

}

static void MX_TIM3_Init(void)
{

  TIM_ClockConfigTypeDef sClockSourceConfig = {0};
  TIM_MasterConfigTypeDef sMasterConfig = {0};
  TIM_OC_InitTypeDef sConfigOC = {0};

  htim3.Instance = TIM3;
  htim3.Init.Prescaler = 99;
  htim3.Init.CounterMode = TIM_COUNTERMODE_UP;
  htim3.Init.Period = 249;
  htim3.Init.ClockDivision = TIM_CLOCKDIVISION_DIV1;
  htim3.Init.AutoReloadPreload = TIM_AUTORELOAD_PRELOAD_DISABLE;
  if (HAL_TIM_Base_Init(&htim3) != HAL_OK)
  {
    Error_Handler();
  }
  sClockSourceConfig.ClockSource = TIM_CLOCKSOURCE_INTERNAL;
  if (HAL_TIM_ConfigClockSource(&htim3, &sClockSourceConfig) != HAL_OK)
  {
    Error_Handler();
  }
  if (HAL_TIM_PWM_Init(&htim3) != HAL_OK)
  {
    Error_Handler();
  }
  sMasterConfig.MasterOutputTrigger = TIM_TRGO_RESET;
  sMasterConfig.MasterSlaveMode = TIM_MASTERSLAVEMODE_DISABLE;
  if (HAL_TIMEx_MasterConfigSynchronization(&htim3, &sMasterConfig) != HAL_OK)
  {
    Error_Handler();
  }
  sConfigOC.OCMode = TIM_OCMODE_PWM1;
  sConfigOC.Pulse = 10;
  sConfigOC.OCPolarity = TIM_OCPOLARITY_HIGH;
  sConfigOC.OCFastMode = TIM_OCFAST_DISABLE;
  if (HAL_TIM_PWM_ConfigChannel(&htim3, &sConfigOC, TIM_CHANNEL_3) != HAL_OK)
  {
    Error_Handler();
  }
  HAL_TIM_MspPostInit(&htim3);

}

static void MX_TIM4_Init(void)
{

  TIM_ClockConfigTypeDef sClockSourceConfig = {0};
  TIM_MasterConfigTypeDef sMasterConfig = {0};
  TIM_OC_InitTypeDef sConfigOC = {0};

  htim4.Instance = TIM4;
  htim4.Init.Prescaler = 199;
  htim4.Init.CounterMode = TIM_COUNTERMODE_UP;
  htim4.Init.Period = 9999;
  htim4.Init.ClockDivision = TIM_CLOCKDIVISION_DIV1;
  htim4.Init.AutoReloadPreload = TIM_AUTORELOAD_PRELOAD_DISABLE;
  if (HAL_TIM_Base_Init(&htim4) != HAL_OK)
  {
    Error_Handler();
  }
  sClockSourceConfig.ClockSource = TIM_CLOCKSOURCE_INTERNAL;
  if (HAL_TIM_ConfigClockSource(&htim4, &sClockSourceConfig) != HAL_OK)
  {
    Error_Handler();
  }
  if (HAL_TIM_PWM_Init(&htim4) != HAL_OK)
  {
    Error_Handler();
  }
  sMasterConfig.MasterOutputTrigger = TIM_TRGO_RESET;
  sMasterConfig.MasterSlaveMode = TIM_MASTERSLAVEMODE_DISABLE;
  if (HAL_TIMEx_MasterConfigSynchronization(&htim4, &sMasterConfig) != HAL_OK)
  {
    Error_Handler();
  }
  sConfigOC.OCMode = TIM_OCMODE_PWM1;
  sConfigOC.Pulse = 1000;
  sConfigOC.OCPolarity = TIM_OCPOLARITY_HIGH;
  sConfigOC.OCFastMode = TIM_OCFAST_DISABLE;
  if (HAL_TIM_PWM_ConfigChannel(&htim4, &sConfigOC, TIM_CHANNEL_1) != HAL_OK)
  {
    Error_Handler();
  }
  sConfigOC.Pulse = 1500;
  if (HAL_TIM_PWM_ConfigChannel(&htim4, &sConfigOC, TIM_CHANNEL_2) != HAL_OK)
  {
    Error_Handler();
  }
  sConfigOC.Pulse = 2000;
  if (HAL_TIM_PWM_ConfigChannel(&htim4, &sConfigOC, TIM_CHANNEL_3) != HAL_OK)
  {
    Error_Handler();
  }
  sConfigOC.Pulse = 2500;
  if (HAL_TIM_PWM_ConfigChannel(&htim4, &sConfigOC, TIM_CHANNEL_4) != HAL_OK)
  {
    Error_Handler();
  }
  HAL_TIM_MspPostInit(&htim4);

}

static void MX_TIM5_Init(void)
{

  TIM_ClockConfigTypeDef sClockSourceConfig = {0};
  TIM_MasterConfigTypeDef sMasterConfig = {0};

  htim5.Instance = TIM5;
  htim5.Init.Prescaler = 199;
  htim5.Init.CounterMode = TIM_COUNTERMODE_UP;
  htim5.Init.Period = 0xFFFFFFFF;
  htim5.Init.ClockDivision = TIM_CLOCKDIVISION_DIV1;
  htim5.Init.AutoReloadPreload = TIM_AUTORELOAD_PRELOAD_DISABLE;
  if (HAL_TIM_Base_Init(&htim5) != HAL_OK)
  {
    Error_Handler();
  }
  sClockSourceConfig.ClockSource = TIM_CLOCKSOURCE_INTERNAL;
  if (HAL_TIM_ConfigClockSource(&htim5, &sClockSourceConfig) != HAL_OK)
  {
    Error_Handler();
  }
  sMasterConfig.MasterOutputTrigger = TIM_TRGO_RESET;
  sMasterConfig.MasterSlaveMode = TIM_MASTERSLAVEMODE_DISABLE;
  if (HAL_TIMEx_MasterConfigSynchronization(&htim5, &sMasterConfig) != HAL_OK)
  {
    Error_Handler();
  }

}

static void MX_TIM6_Init(void)
{

  TIM_MasterConfigTypeDef sMasterConfig = {0};

  htim6.Instance = TIM6;
  htim6.Init.Prescaler = 199;
  htim6.Init.CounterMode = TIM_COUNTERMODE_UP;
  htim6.Init.Period = 9999;
  htim6.Init.AutoReloadPreload = TIM_AUTORELOAD_PRELOAD_DISABLE;
  if (HAL_TIM_Base_Init(&htim6) != HAL_OK)
  {
    Error_Handler();
  }
  sMasterConfig.MasterOutputTrigger = TIM_TRGO_RESET;
  sMasterConfig.MasterSlaveMode = TIM_MASTERSLAVEMODE_DISABLE;
  if (HAL_TIMEx_MasterConfigSynchronization(&htim6, &sMasterConfig) != HAL_OK)
  {
    Error_Handler();
  }

}

static void MX_TIM7_Init(void)
{

  TIM_MasterConfigTypeDef sMasterConfig = {0};

  htim7.Instance = TIM7;
  htim7.Init.Prescaler = 9;
  htim7.Init.CounterMode = TIM_COUNTERMODE_UP;
  htim7.Init.Period = 999;
  htim7.Init.AutoReloadPreload = TIM_AUTORELOAD_PRELOAD_DISABLE;
  if (HAL_TIM_Base_Init(&htim7) != HAL_OK)
  {
    Error_Handler();
  }
  sMasterConfig.MasterOutputTrigger = TIM_TRGO_RESET;
  sMasterConfig.MasterSlaveMode = TIM_MASTERSLAVEMODE_DISABLE;
  if (HAL_TIMEx_MasterConfigSynchronization(&htim7, &sMasterConfig) != HAL_OK)
  {
    Error_Handler();
  }

}

static void MX_UART4_Init(void)
{

  huart4.Instance = UART4;
  huart4.Init.BaudRate = 1500000;
  huart4.Init.WordLength = UART_WORDLENGTH_8B;
  huart4.Init.StopBits = UART_STOPBITS_1;
  huart4.Init.Parity = UART_PARITY_NONE;
  huart4.Init.Mode = UART_MODE_TX_RX;
  huart4.Init.HwFlowCtl = UART_HWCONTROL_NONE;
  huart4.Init.OverSampling = UART_OVERSAMPLING_16;
  huart4.Init.OneBitSampling = UART_ONE_BIT_SAMPLE_DISABLE;
  huart4.Init.ClockPrescaler = UART_PRESCALER_DIV1;
  huart4.AdvancedInit.AdvFeatureInit = UART_ADVFEATURE_NO_INIT;
  if (HAL_UART_Init(&huart4) != HAL_OK)
  {
    Error_Handler();
  }
  if (HAL_UARTEx_SetTxFifoThreshold(&huart4, UART_TXFIFO_THRESHOLD_1_8) != HAL_OK)
  {
    Error_Handler();
  }
  if (HAL_UARTEx_SetRxFifoThreshold(&huart4, UART_RXFIFO_THRESHOLD_1_8) != HAL_OK)
  {
    Error_Handler();
  }
  if (HAL_UARTEx_DisableFifoMode(&huart4) != HAL_OK)
  {
    Error_Handler();
  }

}

static void MX_UART5_Init(void)
{

  huart5.Instance = UART5;
  huart5.Init.BaudRate = 100000;
  huart5.Init.WordLength = UART_WORDLENGTH_9B;
  huart5.Init.StopBits = UART_STOPBITS_2;
  huart5.Init.Parity = UART_PARITY_EVEN;
  huart5.Init.Mode = UART_MODE_TX_RX;
  huart5.Init.HwFlowCtl = UART_HWCONTROL_NONE;
  huart5.Init.OverSampling = UART_OVERSAMPLING_16;
  huart5.Init.OneBitSampling = UART_ONE_BIT_SAMPLE_DISABLE;
  huart5.Init.ClockPrescaler = UART_PRESCALER_DIV1;
  huart5.AdvancedInit.AdvFeatureInit = UART_ADVFEATURE_NO_INIT;
  if (HAL_UART_Init(&huart5) != HAL_OK)
  {
    Error_Handler();
  }
  if (HAL_UARTEx_SetTxFifoThreshold(&huart5, UART_TXFIFO_THRESHOLD_1_8) != HAL_OK)
  {
    Error_Handler();
  }
  if (HAL_UARTEx_SetRxFifoThreshold(&huart5, UART_RXFIFO_THRESHOLD_1_8) != HAL_OK)
  {
    Error_Handler();
  }
  if (HAL_UARTEx_DisableFifoMode(&huart5) != HAL_OK)
  {
    Error_Handler();
  }

}

static void MX_UART7_Init(void)
{

  huart7.Instance = UART7;
  huart7.Init.BaudRate = 115200;
  huart7.Init.WordLength = UART_WORDLENGTH_8B;
  huart7.Init.StopBits = UART_STOPBITS_1;
  huart7.Init.Parity = UART_PARITY_NONE;
  huart7.Init.Mode = UART_MODE_TX_RX;
  huart7.Init.HwFlowCtl = UART_HWCONTROL_NONE;
  huart7.Init.OverSampling = UART_OVERSAMPLING_16;
  huart7.Init.OneBitSampling = UART_ONE_BIT_SAMPLE_DISABLE;
  huart7.Init.ClockPrescaler = UART_PRESCALER_DIV1;
  huart7.AdvancedInit.AdvFeatureInit = UART_ADVFEATURE_NO_INIT;
  if (HAL_UART_Init(&huart7) != HAL_OK)
  {
    Error_Handler();
  }
  if (HAL_UARTEx_SetTxFifoThreshold(&huart7, UART_TXFIFO_THRESHOLD_1_8) != HAL_OK)
  {
    Error_Handler();
  }
  if (HAL_UARTEx_SetRxFifoThreshold(&huart7, UART_RXFIFO_THRESHOLD_1_8) != HAL_OK)
  {
    Error_Handler();
  }
  if (HAL_UARTEx_DisableFifoMode(&huart7) != HAL_OK)
  {
    Error_Handler();
  }

}

static void MX_UART8_Init(void)
{

  huart8.Instance = UART8;
  huart8.Init.BaudRate = 57600;
  huart8.Init.WordLength = UART_WORDLENGTH_8B;
  huart8.Init.StopBits = UART_STOPBITS_1;
  huart8.Init.Parity = UART_PARITY_NONE;
  huart8.Init.Mode = UART_MODE_TX_RX;
  huart8.Init.HwFlowCtl = UART_HWCONTROL_NONE;
  huart8.Init.OverSampling = UART_OVERSAMPLING_16;
  huart8.Init.OneBitSampling = UART_ONE_BIT_SAMPLE_DISABLE;
  huart8.Init.ClockPrescaler = UART_PRESCALER_DIV1;
  huart8.AdvancedInit.AdvFeatureInit = UART_ADVFEATURE_NO_INIT;
  if (HAL_UART_Init(&huart8) != HAL_OK)
  {
    Error_Handler();
  }
  if (HAL_UARTEx_SetTxFifoThreshold(&huart8, UART_TXFIFO_THRESHOLD_1_8) != HAL_OK)
  {
    Error_Handler();
  }
  if (HAL_UARTEx_SetRxFifoThreshold(&huart8, UART_RXFIFO_THRESHOLD_1_8) != HAL_OK)
  {
    Error_Handler();
  }
  if (HAL_UARTEx_DisableFifoMode(&huart8) != HAL_OK)
  {
    Error_Handler();
  }

}

static void MX_USART1_UART_Init(void)
{

  huart1.Instance = USART1;
  huart1.Init.BaudRate = 921600;
  huart1.Init.WordLength = UART_WORDLENGTH_8B;
  huart1.Init.StopBits = UART_STOPBITS_1;
  huart1.Init.Parity = UART_PARITY_NONE;
  huart1.Init.Mode = UART_MODE_TX_RX;
  huart1.Init.HwFlowCtl = UART_HWCONTROL_NONE;
  huart1.Init.OverSampling = UART_OVERSAMPLING_16;
  huart1.Init.OneBitSampling = UART_ONE_BIT_SAMPLE_DISABLE;
  huart1.Init.ClockPrescaler = UART_PRESCALER_DIV1;
  huart1.AdvancedInit.AdvFeatureInit = UART_ADVFEATURE_NO_INIT;
  if (HAL_UART_Init(&huart1) != HAL_OK)
  {
    Error_Handler();
  }
  if (HAL_UARTEx_SetTxFifoThreshold(&huart1, UART_TXFIFO_THRESHOLD_1_8) != HAL_OK)
  {
    Error_Handler();
  }
  if (HAL_UARTEx_SetRxFifoThreshold(&huart1, UART_RXFIFO_THRESHOLD_1_8) != HAL_OK)
  {
    Error_Handler();
  }
  if (HAL_UARTEx_DisableFifoMode(&huart1) != HAL_OK)
  {
    Error_Handler();
  }

}

static void MX_USART2_UART_Init(void)
{

  huart2.Instance = USART2;
  huart2.Init.BaudRate = 230400;
  huart2.Init.WordLength = UART_WORDLENGTH_8B;
  huart2.Init.StopBits = UART_STOPBITS_1;
  huart2.Init.Parity = UART_PARITY_NONE;
  huart2.Init.Mode = UART_MODE_TX_RX;
  huart2.Init.HwFlowCtl = UART_HWCONTROL_NONE;
  huart2.Init.OverSampling = UART_OVERSAMPLING_16;
  huart2.Init.OneBitSampling = UART_ONE_BIT_SAMPLE_DISABLE;
  huart2.Init.ClockPrescaler = UART_PRESCALER_DIV1;
  huart2.AdvancedInit.AdvFeatureInit = UART_ADVFEATURE_NO_INIT;
  if (HAL_UART_Init(&huart2) != HAL_OK)
  {
    Error_Handler();
  }
  if (HAL_UARTEx_SetTxFifoThreshold(&huart2, UART_TXFIFO_THRESHOLD_1_8) != HAL_OK)
  {
    Error_Handler();
  }
  if (HAL_UARTEx_SetRxFifoThreshold(&huart2, UART_RXFIFO_THRESHOLD_1_8) != HAL_OK)
  {
    Error_Handler();
  }
  if (HAL_UARTEx_DisableFifoMode(&huart2) != HAL_OK)
  {
    Error_Handler();
  }

}

static void MX_USART3_UART_Init(void)
{

  huart3.Instance = USART3;
  huart3.Init.BaudRate = 115200;
  huart3.Init.WordLength = UART_WORDLENGTH_8B;
  huart3.Init.StopBits = UART_STOPBITS_1;
  huart3.Init.Parity = UART_PARITY_NONE;
  huart3.Init.Mode = UART_MODE_TX_RX;
  huart3.Init.HwFlowCtl = UART_HWCONTROL_NONE;
  huart3.Init.OverSampling = UART_OVERSAMPLING_16;
  huart3.Init.OneBitSampling = UART_ONE_BIT_SAMPLE_DISABLE;
  huart3.Init.ClockPrescaler = UART_PRESCALER_DIV1;
  huart3.AdvancedInit.AdvFeatureInit = UART_ADVFEATURE_NO_INIT;
  if (HAL_UART_Init(&huart3) != HAL_OK)
  {
    Error_Handler();
  }
  if (HAL_UARTEx_SetTxFifoThreshold(&huart3, UART_TXFIFO_THRESHOLD_1_8) != HAL_OK)
  {
    Error_Handler();
  }
  if (HAL_UARTEx_SetRxFifoThreshold(&huart3, UART_RXFIFO_THRESHOLD_1_8) != HAL_OK)
  {
    Error_Handler();
  }
  if (HAL_UARTEx_DisableFifoMode(&huart3) != HAL_OK)
  {
    Error_Handler();
  }

}

static void MX_USART6_UART_Init(void)
{

  huart6.Instance = USART6;
  huart6.Init.BaudRate = 115200;
  huart6.Init.WordLength = UART_WORDLENGTH_8B;
  huart6.Init.StopBits = UART_STOPBITS_1;
  huart6.Init.Parity = UART_PARITY_NONE;
  huart6.Init.Mode = UART_MODE_TX_RX;
  huart6.Init.HwFlowCtl = UART_HWCONTROL_NONE;
  huart6.Init.OverSampling = UART_OVERSAMPLING_16;
  huart6.Init.OneBitSampling = UART_ONE_BIT_SAMPLE_DISABLE;
  huart6.Init.ClockPrescaler = UART_PRESCALER_DIV1;
  huart6.AdvancedInit.AdvFeatureInit = UART_ADVFEATURE_NO_INIT;
  if (HAL_UART_Init(&huart6) != HAL_OK)
  {
    Error_Handler();
  }
  if (HAL_UARTEx_SetTxFifoThreshold(&huart6, UART_TXFIFO_THRESHOLD_1_8) != HAL_OK)
  {
    Error_Handler();
  }
  if (HAL_UARTEx_SetRxFifoThreshold(&huart6, UART_RXFIFO_THRESHOLD_1_8) != HAL_OK)
  {
    Error_Handler();
  }
  if (HAL_UARTEx_DisableFifoMode(&huart6) != HAL_OK)
  {
    Error_Handler();
  }

}

static void MX_DMA_Init(void)
{

  /* DMA controller clock enable */
  __HAL_RCC_DMA1_CLK_ENABLE();
  __HAL_RCC_DMA2_CLK_ENABLE();

  /* DMA interrupt init */
  /* DMA1_Stream0_IRQn interrupt configuration */
  HAL_NVIC_SetPriority(DMA1_Stream0_IRQn, 5, 0);
  HAL_NVIC_EnableIRQ(DMA1_Stream0_IRQn);
  /* DMA1_Stream1_IRQn interrupt configuration */
  HAL_NVIC_SetPriority(DMA1_Stream1_IRQn, 5, 0);
  HAL_NVIC_EnableIRQ(DMA1_Stream1_IRQn);
  /* DMA1_Stream2_IRQn interrupt configuration */
  HAL_NVIC_SetPriority(DMA1_Stream2_IRQn, 5, 0);
  HAL_NVIC_EnableIRQ(DMA1_Stream2_IRQn);
  /* DMA1_Stream3_IRQn interrupt configuration */
  HAL_NVIC_SetPriority(DMA1_Stream3_IRQn, 5, 0);
  HAL_NVIC_EnableIRQ(DMA1_Stream3_IRQn);
  /* DMA1_Stream4_IRQn interrupt configuration */
  HAL_NVIC_SetPriority(DMA1_Stream4_IRQn, 5, 0);
  HAL_NVIC_EnableIRQ(DMA1_Stream4_IRQn);
  /* DMA1_Stream5_IRQn interrupt configuration */
  HAL_NVIC_SetPriority(DMA1_Stream5_IRQn, 5, 0);
  HAL_NVIC_EnableIRQ(DMA1_Stream5_IRQn);
  /* DMA1_Stream6_IRQn interrupt configuration */
  HAL_NVIC_SetPriority(DMA1_Stream6_IRQn, 5, 0);
  HAL_NVIC_EnableIRQ(DMA1_Stream6_IRQn);
  /* DMA2_Stream0_IRQn interrupt configuration */
  HAL_NVIC_SetPriority(DMA2_Stream0_IRQn, 5, 0);
  HAL_NVIC_EnableIRQ(DMA2_Stream0_IRQn);

}

static void MX_GPIO_Init(void)
{
  GPIO_InitTypeDef GPIO_InitStruct = {0};

  /* GPIO Ports Clock Enable */
  __HAL_RCC_GPIOE_CLK_ENABLE();
  __HAL_RCC_GPIOC_CLK_ENABLE();
  __HAL_RCC_GPIOH_CLK_ENABLE();
  __HAL_RCC_GPIOA_CLK_ENABLE();
  __HAL_RCC_GPIOB_CLK_ENABLE();
  __HAL_RCC_GPIOD_CLK_ENABLE();

  /*Configure GPIO pin Output Level */
  HAL_GPIO_WritePin(GPIOE, IMU_D0_Pin|IMU_D1_Pin|IMU_D2_Pin|IMU_D3_Pin
                          |RS232_IO1_Pin|RS232_IO2_Pin, GPIO_PIN_RESET);

  /*Configure GPIO pin Output Level */
  HAL_GPIO_WritePin(GPIOE, SPI2_CS_Pin|SIGNAL_Pin|RS232_OFF_Pin|RS232_ON_Pin, GPIO_PIN_SET);

  /*Configure GPIO pin Output Level */
  HAL_GPIO_WritePin(SPI2_IO_GPIO_Port, SPI2_IO_Pin, GPIO_PIN_RESET);

  /*Configure GPIO pin Output Level */
  HAL_GPIO_WritePin(S_EN_GPIO_Port, S_EN_Pin, GPIO_PIN_SET);

  /*Configure GPIO pin Output Level */
  HAL_GPIO_WritePin(GPIOC, ADXL_CS_Pin|ADXL_INT_Pin, GPIO_PIN_SET);

  /*Configure GPIO pin Output Level */
  HAL_GPIO_WritePin(GPIOB, TELEM2_IO1_Pin|TELEM2_IO2_Pin|BAT3_Pin|TELEM3_IO2_Pin
                          |TELEM3_IO1_Pin, GPIO_PIN_RESET);

  /*Configure GPIO pin Output Level */
  HAL_GPIO_WritePin(GPIOB, BAT4_Pin|TRIGGER_Pin, GPIO_PIN_SET);

  /*Configure GPIO pin Output Level */
  HAL_GPIO_WritePin(GPIOD, BAT2_Pin|BAT1_Pin|TELEM1_IO2_Pin|TELEM1_IO1_Pin, GPIO_PIN_RESET);

  /*Configure GPIO pins : IMU_D0_Pin IMU_D1_Pin IMU_D2_Pin IMU_D3_Pin
                           SIGNAL_Pin RS232_IO1_Pin RS232_IO2_Pin */
  GPIO_InitStruct.Pin = IMU_D0_Pin|IMU_D1_Pin|IMU_D2_Pin|IMU_D3_Pin
                          |SIGNAL_Pin|RS232_IO1_Pin|RS232_IO2_Pin;
  GPIO_InitStruct.Mode = GPIO_MODE_OUTPUT_PP;
  GPIO_InitStruct.Pull = GPIO_PULLDOWN;
  GPIO_InitStruct.Speed = GPIO_SPEED_FREQ_LOW;
  HAL_GPIO_Init(GPIOE, &GPIO_InitStruct);

  /*Configure GPIO pin : SPI2_CS_Pin */
  GPIO_InitStruct.Pin = SPI2_CS_Pin;
  GPIO_InitStruct.Mode = GPIO_MODE_OUTPUT_PP;
  GPIO_InitStruct.Pull = GPIO_PULLUP;
  GPIO_InitStruct.Speed = GPIO_SPEED_FREQ_HIGH;
  HAL_GPIO_Init(SPI2_CS_GPIO_Port, &GPIO_InitStruct);

  /*Configure GPIO pin : SPI2_IO_Pin */
  GPIO_InitStruct.Pin = SPI2_IO_Pin;
  GPIO_InitStruct.Mode = GPIO_MODE_OUTPUT_PP;
  GPIO_InitStruct.Pull = GPIO_PULLDOWN;
  GPIO_InitStruct.Speed = GPIO_SPEED_FREQ_LOW;
  HAL_GPIO_Init(SPI2_IO_GPIO_Port, &GPIO_InitStruct);

  /*Configure GPIO pin : S_EN_Pin */
  GPIO_InitStruct.Pin = S_EN_Pin;
  GPIO_InitStruct.Mode = GPIO_MODE_OUTPUT_OD;
  GPIO_InitStruct.Pull = GPIO_NOPULL;
  GPIO_InitStruct.Speed = GPIO_SPEED_FREQ_LOW;
  HAL_GPIO_Init(S_EN_GPIO_Port, &GPIO_InitStruct);

  /*Configure GPIO pins : ADXL_CS_Pin ADXL_INT_Pin */
  GPIO_InitStruct.Pin = ADXL_CS_Pin|ADXL_INT_Pin;
  GPIO_InitStruct.Mode = GPIO_MODE_OUTPUT_PP;
  GPIO_InitStruct.Pull = GPIO_PULLUP;
  GPIO_InitStruct.Speed = GPIO_SPEED_FREQ_HIGH;
  HAL_GPIO_Init(GPIOC, &GPIO_InitStruct);

  /*Configure GPIO pins : TELEM2_IO1_Pin TELEM2_IO2_Pin TELEM3_IO2_Pin TELEM3_IO1_Pin */
  GPIO_InitStruct.Pin = TELEM2_IO1_Pin|TELEM2_IO2_Pin|TELEM3_IO2_Pin|TELEM3_IO1_Pin;
  GPIO_InitStruct.Mode = GPIO_MODE_OUTPUT_PP;
  GPIO_InitStruct.Pull = GPIO_PULLDOWN;
  GPIO_InitStruct.Speed = GPIO_SPEED_FREQ_LOW;
  HAL_GPIO_Init(GPIOB, &GPIO_InitStruct);

  /*Configure GPIO pins : RS232_VALID_Pin RS232_RDY_Pin */
  GPIO_InitStruct.Pin = RS232_VALID_Pin|RS232_RDY_Pin;
  GPIO_InitStruct.Mode = GPIO_MODE_INPUT;
  GPIO_InitStruct.Pull = GPIO_NOPULL;
  HAL_GPIO_Init(GPIOE, &GPIO_InitStruct);

  /*Configure GPIO pins : RS232_OFF_Pin RS232_ON_Pin */
  GPIO_InitStruct.Pin = RS232_OFF_Pin|RS232_ON_Pin;
  GPIO_InitStruct.Mode = GPIO_MODE_OUTPUT_PP;
  GPIO_InitStruct.Pull = GPIO_NOPULL;
  GPIO_InitStruct.Speed = GPIO_SPEED_FREQ_LOW;
  HAL_GPIO_Init(GPIOE, &GPIO_InitStruct);

  /*Configure GPIO pins : BAT4_Pin BAT3_Pin */
  GPIO_InitStruct.Pin = BAT4_Pin|BAT3_Pin;
  GPIO_InitStruct.Mode = GPIO_MODE_OUTPUT_PP;
  GPIO_InitStruct.Pull = GPIO_PULLDOWN;
  GPIO_InitStruct.Speed = GPIO_SPEED_FREQ_HIGH;
  HAL_GPIO_Init(GPIOB, &GPIO_InitStruct);

  /*Configure GPIO pins : BAT2_Pin BAT1_Pin */
  GPIO_InitStruct.Pin = BAT2_Pin|BAT1_Pin;
  GPIO_InitStruct.Mode = GPIO_MODE_OUTPUT_PP;
  GPIO_InitStruct.Pull = GPIO_PULLDOWN;
  GPIO_InitStruct.Speed = GPIO_SPEED_FREQ_HIGH;
  HAL_GPIO_Init(GPIOD, &GPIO_InitStruct);

  /*Configure GPIO pins : TELEM1_IO2_Pin TELEM1_IO1_Pin */
  GPIO_InitStruct.Pin = TELEM1_IO2_Pin|TELEM1_IO1_Pin;
  GPIO_InitStruct.Mode = GPIO_MODE_OUTPUT_PP;
  GPIO_InitStruct.Pull = GPIO_PULLDOWN;
  GPIO_InitStruct.Speed = GPIO_SPEED_FREQ_LOW;
  HAL_GPIO_Init(GPIOD, &GPIO_InitStruct);

  /*Configure GPIO pin : PA8 */
  GPIO_InitStruct.Pin = GPIO_PIN_8;
  GPIO_InitStruct.Mode = GPIO_MODE_AF_PP;
  GPIO_InitStruct.Pull = GPIO_NOPULL;
  GPIO_InitStruct.Speed = GPIO_SPEED_FREQ_LOW;
  GPIO_InitStruct.Alternate = GPIO_AF0_MCO;
  HAL_GPIO_Init(GPIOA, &GPIO_InitStruct);

  /*Configure GPIO pin : SDIO_CD_Pin */
  GPIO_InitStruct.Pin = SDIO_CD_Pin;
  GPIO_InitStruct.Mode = GPIO_MODE_INPUT;
  GPIO_InitStruct.Pull = GPIO_NOPULL;
  HAL_GPIO_Init(SDIO_CD_GPIO_Port, &GPIO_InitStruct);

  /*Configure GPIO pin : TRIGGER_Pin */
  GPIO_InitStruct.Pin = TRIGGER_Pin;
  GPIO_InitStruct.Mode = GPIO_MODE_OUTPUT_PP;
  GPIO_InitStruct.Pull = GPIO_PULLDOWN;
  GPIO_InitStruct.Speed = GPIO_SPEED_FREQ_VERY_HIGH;
  HAL_GPIO_Init(TRIGGER_GPIO_Port, &GPIO_InitStruct);

}

void StartDefaultTask(void const * argument)
{
  for(;;)
  {
    osDelay(1);
  }
}

void HAL_TIM_PeriodElapsedCallback(TIM_HandleTypeDef *htim)
{
  if (htim->Instance == TIM17) {
    HAL_IncTick();
  }
  /* USER CODE BEGIN Callback 1 */
	if (htim->Instance == TIM7) {
    FreeRTOSRunTimeTicks++;
  }

	if (htim->Instance == TIM6) {
		ControlUpdata();
//		ControlTime += ControlDt;
//		xSemaphoreGiveFromISR(ControlSemaphore,&GNSSHigherTaskSwitch);
//		portYIELD_FROM_ISR(ControlHigherTaskSwitch);
	}
  /* USER CODE END Callback 1 */
}

void Error_Handler(void)
{
  __disable_irq();
  while (1)
  {
  }
}

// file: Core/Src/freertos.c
/* USER CODE BEGIN Header */
/**
  ******************************************************************************
  * File Name          : freertos.c
  * Description        : Code for freertos applications
  ******************************************************************************
  * @attention
  *
  * Copyright (c) 2023 STMicroelectronics.
  * All rights reserved.
  *
  * This software is licensed under terms that can be found in the LICENSE file
  * in the root directory of this software component.
  * If no LICENSE file comes with this software, it is provided AS-IS.
  *
  ******************************************************************************
  */
/* USER CODE END Header */

#include "FreeRTOS.h"
#include "task.h"
#include "main.h"

/* GetIdleTaskMemory prototype (linked to static allocation support) */
void vApplicationGetIdleTaskMemory( StaticTask_t **ppxIdleTaskTCBBuffer, StackType_t **ppxIdleTaskStackBuffer, uint32_t *pulIdleTaskStackSize );

/* Hook prototypes */
void configureTimerForRunTimeStats(void);
unsigned long getRunTimeCounterValue(void);

/* USER CODE BEGIN 1 */
/* Functions needed when configGENERATE_RUN_TIME_STATS is on */
__weak void configureTimerForRunTimeStats(void)
{
	FreeRTOSRunTimeTicks = 0;
//	HAL_TIM_Base_Start_IT(&htim7);//�?启RunTime统计时钟;
}

__weak unsigned long getRunTimeCounterValue(void)
{
	return FreeRTOSRunTimeTicks;
}
/* USER CODE END 1 */

/* USER CODE BEGIN GET_IDLE_TASK_MEMORY */
static StaticTask_t xIdleTaskTCBBuffer;
static StackType_t xIdleStack[configMINIMAL_STACK_SIZE];

void vApplicationGetIdleTaskMemory( StaticTask_t **ppxIdleTaskTCBBuffer, StackType_t **ppxIdleTaskStackBuffer, uint32_t *pulIdleTaskStackSize )
{
  *ppxIdleTaskTCBBuffer = &xIdleTaskTCBBuffer;
  *ppxIdleTaskStackBuffer = &xIdleStack[0];
  *pulIdleTaskStackSize = configMINIMAL_STACK_SIZE;
  /* place for user code */
}
/* USER CODE END GET_IDLE_TASK_MEMORY */
